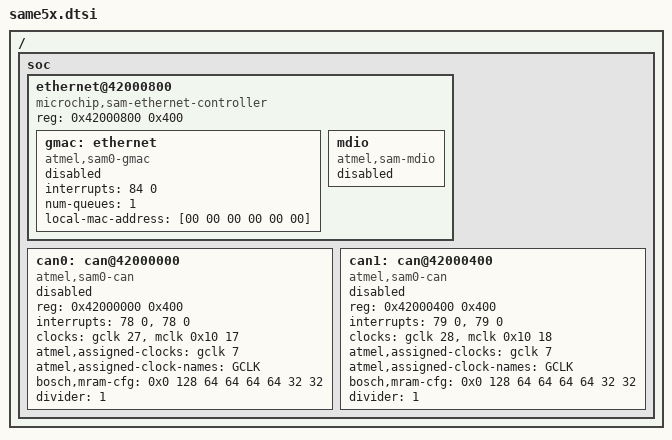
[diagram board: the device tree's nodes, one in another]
/*
 * Copyright (c) 2020 Stephanos Ioannidis <root@stephanos.io>
 * Copyright (c) 2023 Sebastian Schlupp
 * Copyright (c) 2024 Gerson Fernando Budke <nandojve@gmail.com>
 *
 * SPDX-License-Identifier: Apache-2.0
 */

#include <atmel/samd5x.dtsi>

/ {
	soc {
		ethernet@42000800 {
			compatible = "microchip,sam-ethernet-controller";
			reg = <0x42000800 0x400>;

			gmac: ethernet {
				compatible = "atmel,sam0-gmac";
				interrupts = <84 0>;
				interrupt-names = "gmac";
				status = "disabled";

				num-queues = <1>;
				local-mac-address = [00 00 00 00 00 00];
			};

			mdio: mdio {
				compatible = "atmel,sam-mdio";
				status = "disabled";

				#address-cells = <1>;
				#size-cells = <0>;
			};
		};

		can0: can@42000000 {
			compatible = "atmel,sam0-can";
			reg = <0x42000000 0x400>;
			interrupts = <78 0>, <78 0>;
			interrupt-names = "int0", "int1";
			clocks = <&gclk 27>, <&mclk 0x10 17>;
			clock-names = "GCLK", "MCLK";
			atmel,assigned-clocks = <&gclk 7>;
			atmel,assigned-clock-names = "GCLK";
			status = "disabled";

			bosch,mram-cfg = <0x0 128 64 64 64 64 32 32>;
			divider = <1>;
		};

		can1: can@42000400 {
			compatible = "atmel,sam0-can";
			reg = <0x42000400 0x400>;
			interrupts = <79 0>, <79 0>;
			interrupt-names = "int0", "int1";
			clocks = <&gclk 28>, <&mclk 0x10 18>;
			clock-names = "GCLK", "MCLK";
			atmel,assigned-clocks = <&gclk 7>;
			atmel,assigned-clock-names = "GCLK";
			status = "disabled";

			bosch,mram-cfg = <0x0 128 64 64 64 64 32 32>;
			divider = <1>;
		};
	};
};
